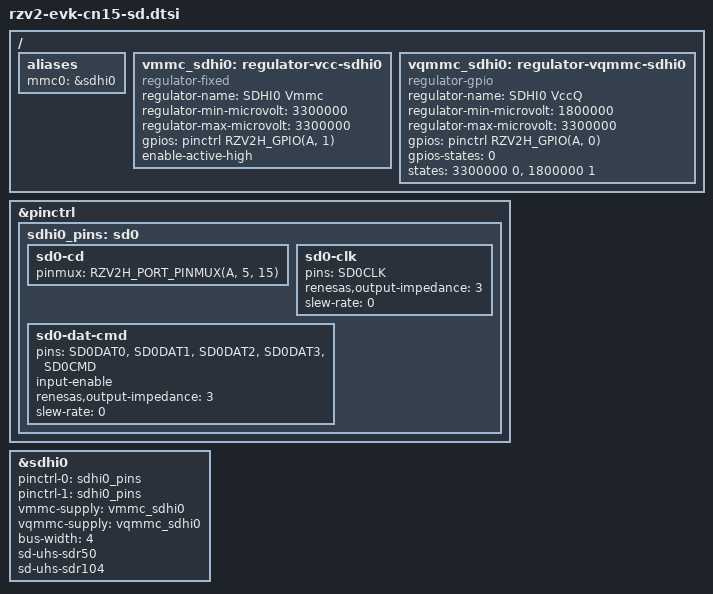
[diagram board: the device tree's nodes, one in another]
// SPDX-License-Identifier: GPL-2.0
/*
 * Shared DTSI for the microSD Sub Board (RTK0EF0186B01000BJ), which
 * is connected to the CN15 connector on the RZ/V2H and RZ/V2N EVKs.
 *
 * Copyright (C) 2025 Renesas Electronics Corp.
 */

/ {
	aliases {
		mmc0 = &sdhi0;
	};


	vmmc_sdhi0: regulator-vcc-sdhi0 {
		compatible = "regulator-fixed";

		regulator-name = "SDHI0 Vmmc";
		regulator-min-microvolt = <3300000>;
		regulator-max-microvolt = <3300000>;

		gpios = <&pinctrl RZV2H_GPIO(A, 1) GPIO_ACTIVE_HIGH>;
		enable-active-high;
	};

	vqmmc_sdhi0: regulator-vqmmc-sdhi0 {
		compatible = "regulator-gpio";

		regulator-name = "SDHI0 VccQ";
		regulator-min-microvolt = <1800000>;
		regulator-max-microvolt = <3300000>;

		gpios = <&pinctrl RZV2H_GPIO(A, 0) GPIO_ACTIVE_HIGH>;

		gpios-states = <0>;
		states = <3300000 0>, <1800000 1>;
	};
};

&pinctrl {
	sdhi0_pins: sd0 {
		sd0-cd {
			pinmux = <RZV2H_PORT_PINMUX(A, 5, 15)>; /* SD0_CD */
		};

		sd0-clk {
			pins = "SD0CLK";
			renesas,output-impedance = <3>;
			slew-rate = <0>;
		};

		sd0-dat-cmd {
			pins = "SD0DAT0", "SD0DAT1", "SD0DAT2", "SD0DAT3", "SD0CMD";
			input-enable;
			renesas,output-impedance = <3>;
			slew-rate = <0>;
		};
	};
};

&sdhi0 {
	pinctrl-0 = <&sdhi0_pins>;
	pinctrl-1 = <&sdhi0_pins>;
	pinctrl-names = "default", "state_uhs";
	vmmc-supply = <&vmmc_sdhi0>;
	vqmmc-supply = <&vqmmc_sdhi0>;
	bus-width = <4>;
	sd-uhs-sdr50;
	sd-uhs-sdr104;
	status = "okay";
};
